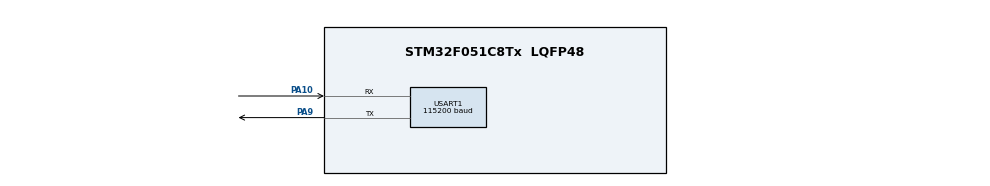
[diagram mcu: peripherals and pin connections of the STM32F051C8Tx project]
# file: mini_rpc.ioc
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FREERTOS.Tasks01=defaultTask,24,128,StartDefaultTask,Default,NULL,Dynamic,NULL,NULL;Server_Task,24,128,StartTask02,Default,NULL,Dynamic,NULL,NULL;Client_Task,24,128,StartTask03,Default,NULL,Dynamic,NULL,NULL
FREERTOS.configMINIMAL_STACK_SIZE=128
FREERTOS.configTOTAL_HEAP_SIZE=1920
Mcu.Family=STM32F0
Mcu.Name=STM32F051C8Tx
Mcu.Package=LQFP48
NVIC.TIM6_DAC_IRQn=true\:3\:0\:false\:false\:true\:false\:false\:true\:true
NVIC.TimeBase=TIM6_DAC_IRQn
NVIC.TimeBaseIP=TIM6
NVIC.USART1_IRQn=true\:3\:0\:false\:false\:true\:true\:true\:true\:true
PA10.Mode=Asynchronous
PA10.Signal=USART1_RX
PA13.Mode=Serial_Wire
PA13.Signal=SYS_SWDIO
PA14.Mode=Serial_Wire
PA14.Signal=SYS_SWCLK
PA9.Mode=Asynchronous
PA9.Signal=USART1_TX
ProjectManager.HeapSize=0x200
ProjectManager.StackSize=0x400
ProjectManager.TargetToolchain=EWARM V8.32
USART1.BaudRate=115200
USART1.VirtualMode-Asynchronous=VM_ASYNC
VP_FREERTOS_VS_CMSIS_V2.Mode=CMSIS_V2
VP_SYS_VS_tim6.Mode=TIM6
board=custom

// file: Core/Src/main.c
/* USER CODE BEGIN Header */
/**
  ******************************************************************************
  * @file           : main.c
  * @brief          : Main program body
  ******************************************************************************
  * @attention
  *
  * Copyright (c) 2025 STMicroelectronics.
  * All rights reserved.
  *
  * This software is licensed under terms that can be found in the LICENSE file
  * in the root directory of this software component.
  * If no LICENSE file comes with this software, it is provided AS-IS.
  *
  ******************************************************************************
  */
/* USER CODE END Header */
#include "main.h"
#include "cmsis_os.h"

/* USER CODE BEGIN Includes */
#include <user_main.h>
/* USER CODE END Includes */

UART_HandleTypeDef huart1;

/* Definitions for defaultTask */
osThreadId_t defaultTaskHandle;
const osThreadAttr_t defaultTask_attributes = {
  .name = "defaultTask",
  .stack_size = 128 * 4,
  .priority = (osPriority_t) osPriorityNormal,
};
/* Definitions for Server_Task */
osThreadId_t Server_TaskHandle;
const osThreadAttr_t Server_Task_attributes = {
  .name = "Server_Task",
  .stack_size = 128 * 4,
  .priority = (osPriority_t) osPriorityNormal,
};
/* Definitions for Client_Task */
osThreadId_t Client_TaskHandle;
const osThreadAttr_t Client_Task_attributes = {
  .name = "Client_Task",
  .stack_size = 128 * 4,
  .priority = (osPriority_t) osPriorityNormal,
};

void SystemClock_Config(void);
static void MX_GPIO_Init(void);
static void MX_USART1_UART_Init(void);
void StartDefaultTask(void *argument);
void StartTask02(void *argument);
void StartTask03(void *argument);

int main(void)
{

  /* MCU Configuration--------------------------------------------------------*/

  /* Reset of all peripherals, Initializes the Flash interface and the Systick. */
  HAL_Init();

  /* Configure the system clock */
  SystemClock_Config();

  /* Initialize all configured peripherals */
  MX_GPIO_Init();
  MX_USART1_UART_Init();

  /* Init scheduler */
  osKernelInitialize();

  /* Create the thread(s) */
  /* creation of defaultTask */
  defaultTaskHandle = osThreadNew(StartDefaultTask, NULL, &defaultTask_attributes);

  /* creation of Server_Task */
  Server_TaskHandle = osThreadNew(StartTask02, NULL, &Server_Task_attributes);

  /* creation of Client_Task */
  Client_TaskHandle = osThreadNew(StartTask03, NULL, &Client_Task_attributes);

  /* Start scheduler */
  osKernelStart();

  /* We should never get here as control is now taken by the scheduler */

  /* Infinite loop */
  /* USER CODE BEGIN WHILE */

  user_main_function();

  while (1)
  {
    /* USER CODE END WHILE */

  }
}

void SystemClock_Config(void)
{
  RCC_OscInitTypeDef RCC_OscInitStruct = {0};
  RCC_ClkInitTypeDef RCC_ClkInitStruct = {0};
  RCC_PeriphCLKInitTypeDef PeriphClkInit = {0};

  /** Initializes the RCC Oscillators according to the specified parameters
  * in the RCC_OscInitTypeDef structure.
  */
  RCC_OscInitStruct.OscillatorType = RCC_OSCILLATORTYPE_HSI;
  RCC_OscInitStruct.HSIState = RCC_HSI_ON;
  RCC_OscInitStruct.HSICalibrationValue = RCC_HSICALIBRATION_DEFAULT;
  RCC_OscInitStruct.PLL.PLLState = RCC_PLL_NONE;
  if (HAL_RCC_OscConfig(&RCC_OscInitStruct) != HAL_OK)
  {
    Error_Handler();
  }

  /** Initializes the CPU, AHB and APB buses clocks
  */
  RCC_ClkInitStruct.ClockType = RCC_CLOCKTYPE_HCLK|RCC_CLOCKTYPE_SYSCLK
                              |RCC_CLOCKTYPE_PCLK1;
  RCC_ClkInitStruct.SYSCLKSource = RCC_SYSCLKSOURCE_HSI;
  RCC_ClkInitStruct.AHBCLKDivider = RCC_SYSCLK_DIV1;
  RCC_ClkInitStruct.APB1CLKDivider = RCC_HCLK_DIV1;

  if (HAL_RCC_ClockConfig(&RCC_ClkInitStruct, FLASH_LATENCY_0) != HAL_OK)
  {
    Error_Handler();
  }
  PeriphClkInit.PeriphClockSelection = RCC_PERIPHCLK_USART1;
  PeriphClkInit.Usart1ClockSelection = RCC_USART1CLKSOURCE_PCLK1;
  if (HAL_RCCEx_PeriphCLKConfig(&PeriphClkInit) != HAL_OK)
  {
    Error_Handler();
  }
}

static void MX_USART1_UART_Init(void)
{

  huart1.Instance = USART1;
  huart1.Init.BaudRate = 115200;
  huart1.Init.WordLength = UART_WORDLENGTH_8B;
  huart1.Init.StopBits = UART_STOPBITS_1;
  huart1.Init.Parity = UART_PARITY_NONE;
  huart1.Init.Mode = UART_MODE_TX_RX;
  huart1.Init.HwFlowCtl = UART_HWCONTROL_NONE;
  huart1.Init.OverSampling = UART_OVERSAMPLING_16;
  huart1.Init.OneBitSampling = UART_ONE_BIT_SAMPLE_DISABLE;
  huart1.AdvancedInit.AdvFeatureInit = UART_ADVFEATURE_NO_INIT;
  if (HAL_UART_Init(&huart1) != HAL_OK)
  {
    Error_Handler();
  }

}

static void MX_GPIO_Init(void)
{

  /* GPIO Ports Clock Enable */
  __HAL_RCC_GPIOA_CLK_ENABLE();

}

void StartDefaultTask(void *argument)
{
  for(;;)
  {
    osDelay(1);
  }
}

void StartTask02(void *argument)
{
  for(;;)
  {
    osDelay(1);
  }
}

void StartTask03(void *argument)
{
  for(;;)
  {
    osDelay(1);
  }
}

void HAL_TIM_PeriodElapsedCallback(TIM_HandleTypeDef *htim)
{
  if (htim->Instance == TIM6)
  {
    HAL_IncTick();
  }
}

void Error_Handler(void)
{
  __disable_irq();
  while (1)
  {
  }
}
